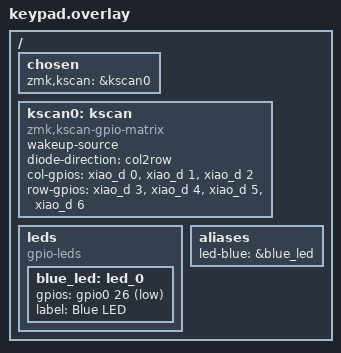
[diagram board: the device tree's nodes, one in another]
/ {
    chosen {
        zmk,kscan = &kscan0;
    };

    kscan0: kscan {
        compatible = "zmk,kscan-gpio-matrix";
        wakeup-source;
        diode-direction = "col2row"; // Required even without physical diodes

        col-gpios
            = <&xiao_d 0 GPIO_ACTIVE_HIGH>
            , <&xiao_d 1 GPIO_ACTIVE_HIGH>
            , <&xiao_d 2 GPIO_ACTIVE_HIGH>
            ;

        row-gpios
            = <&xiao_d 3 (GPIO_ACTIVE_HIGH | GPIO_PULL_DOWN)>
            , <&xiao_d 4 (GPIO_ACTIVE_HIGH | GPIO_PULL_DOWN)>
            , <&xiao_d 5 (GPIO_ACTIVE_HIGH | GPIO_PULL_DOWN)>
            , <&xiao_d 6 (GPIO_ACTIVE_HIGH | GPIO_PULL_DOWN)>
            ;
    };
};

/ {
    leds {
        compatible = "gpio-leds";
        blue_led: led_0 {
            gpios = <&gpio0 26 GPIO_ACTIVE_LOW>;
            label = "Blue LED";
        };
    };

    /* Define the LED as the Bluetooth status indicator */
    aliases {
        led-blue = &blue_led;
    };
};
